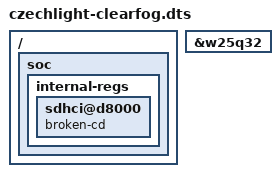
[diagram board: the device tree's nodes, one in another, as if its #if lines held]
#include "../../../include/generated/uapi/linux/version.h"
#if (LINUX_VERSION_CODE < KERNEL_VERSION(6, 5, 0))
#include "armada-388-clearfog-base.dts"
#else
#include "marvell/armada-388-clearfog-base.dts"
#endif

&w25q32 {
	status = "okay";
	/* FIXME: need to ensure that CS2 is high when probing for this... */
};

/ {
	soc {
		internal-regs {
			sdhci@d8000 {
				/delete-property/ cd-gpios;
				broken-cd;
			};
		};
	};
};
